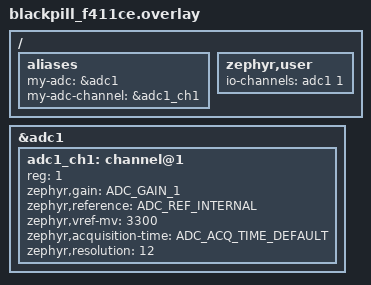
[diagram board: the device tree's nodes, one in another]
/ {
    aliases {
        my-adc = &adc1;
        my-adc-channel = &adc1_ch1;
    };

	zephyr,user {
		/* adjust channel number according to pinmux in board.dts */
		io-channels = <&adc1 1>;
	};
};


// ADC1 (ADC0) channel 0 is connected to A0
&adc1 {
    status = "okay";
    #address-cells = <1>;
    #size-cells = <0>;

    adc1_ch1: channel@1 {
        reg = <1>;
        zephyr,gain = "ADC_GAIN_1";
        zephyr,reference = "ADC_REF_INTERNAL";
        zephyr,vref-mv = <3300>;
        zephyr,acquisition-time = <ADC_ACQ_TIME_DEFAULT>;
        zephyr,resolution = <12>;
    };
};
